# PIC32MM0064GPM064 device description
Architecture: MIPS; Family: PIC32MM1387; Series: PIC32MM
Registers are 32-bit, read-write, no defined reset value unless marked. A register's access mark holds for its fields unless they carry their own. Offsets are from the block's base; [hi:lo] are bit positions; {n}, {i} and the like mark numbered series; 'fields as' and 'values as' point back to an identical list.

## CLC
Instances: CLC 0x1f802480 in periph0
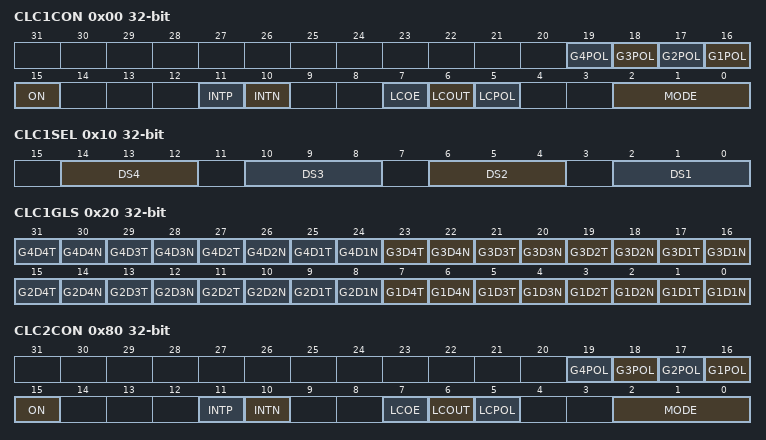
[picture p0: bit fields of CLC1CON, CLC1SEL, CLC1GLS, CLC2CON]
0x00 CLC1CON
  [n+15] G{n}POL (n=1..4) — Gate {n} Polarity Control bit
    1=The output of Channel {n} logic is inverted when applied to the logic cell; 0=The output of Channel {n} logic is not inverted
  [15] ON — CLCx Enable bit
    1=CLCx is enabled and mixing input signals; 0=CLCx is disabled and has logic zero outputs
  [11] INTP — CLCx Positive Edge Interrupt Enable bit
    1=Interrupt will be generated when a rising edge occurs on LCOUT; 0=Interrupt will not be generated
  [10] INTN — CLCx Negative Edge Interrupt Enable bit
    1=Interrupt will be generated when a falling edge occurs on LCOUT; 0=Interrupt will not be generated
  [7] LCOE — CLCx Port Enable bit
    1=CLCx port pin output is enabled; 0=CLCx port pin output is disabled
  [6] LCOUT — CLCx Data Output Status bit
    1=CLCx output high; 0=CLCx output low
  [5] LCPOL — CLCx Output Polarity Control bit
    1=The output of the module is inverted; 0=The output of the module is not inverted
  [2:0] MODE — CLCx Mode bits
    7=Cell is a 1-input transparent latch with S and R; 6=Cell is a JK flip-flop with R; 5=Cell is a 2-input D flip-flop with R; 4=Cell is a 1-input D flip-flop with S and R; 3=Cell is an SR latch; 2=Cell is a 4-input AND; 1=Cell is an OR-XOR; 0=Cell is a AND-OR
0x10 CLC1SEL
  [14:12] DS4 — Data Selection MUX 4 Signal Selection bits
    7=SCCP5 OCMP compare match event; 6=MCCP1 OCMP compare match event; 5=RTCC event; 4=CMP3 out; 3=SPI1 SDI1 in; 2=SCCP5 OCM5 output; 1=CLC2 out; 0=CLCINB I/O pin
  [10:8] DS3 — Data Selection MUX 3 Signal Selection bits
    7=SCCP5 OCMP compare match event; 6=SCCP4 OCMP compare match event; 5=SCCP4 OCM4 output; 4=UART1 RX In; 3=SPI1 SDO1 Out; 2=CMP2 out; 1=CLC1 Out; 0=CLCINA I/O pin
  [6:4] DS2 — Data Selection MUX 2 Signal Selection bits
    6=MCCP1 OCMP compare match event; 5=DMA Channel 0 interrupt; 4=ADC End of Conversion; 3=UART1 TX Out; 2=CMP1 out; 1=CLC2 out; 0=CLCINB I/O pin
  [2:0] DS1 — Data Selection MUX 1 Signal Selection bits
    7=MCCP1 OCM1C Output; 6=MCCP1 OCM1B Output; 5=MCCP1 OCM1A Output; 4=REFO1 Clock Output; 3=LPRC Clock; 2=SOSC Clock; 1=System Clock; 0=CLCINA I/O pin
0x20 CLC1GLS
  [8n-1] G{n}D4T (n=1..4), [8n-2] G{n}D4N (n=1..4), [8n-3] G{n}D3T (n=1..4), [8n-4] G{n}D3N (n=1..4), [8n-5] G{n}D2T (n=1..4), [8n-6] G{n}D2N (n=1..4), [8n-7] G{n}D1T (n=1..4), [8n-8] G{n}D1N (n=1..4)
0x80 CLC2CON
  fields as CLC1CON
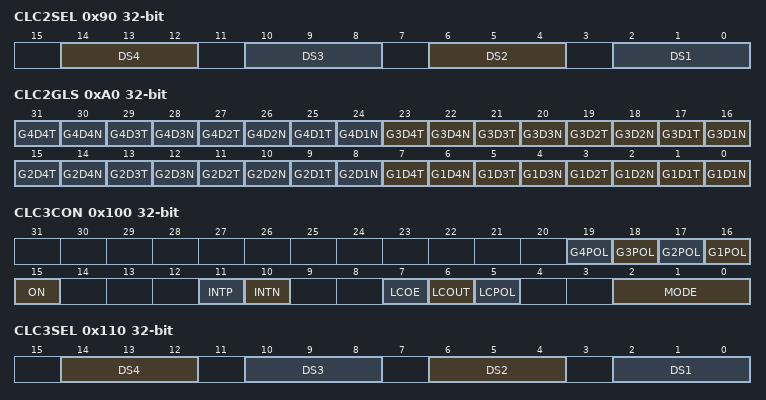
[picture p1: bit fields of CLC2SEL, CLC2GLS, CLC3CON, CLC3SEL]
0x90 CLC2SEL
  [14:12] DS4 — Data Selection MUX 4 Signal Selection bits
    7=SCCP5 OCMP compare match event; 6=MCCP1 OCMP compare match event; 5=RTCC event; 4=CMP3 out; 3=SPI2 SDI2 in; 2=SCCP5 OCM5 Output; 1=CLC1 out; 0=CLCINB I/O pin
  [10:8] DS3 — Data Selection MUX 3 Signal Selection bits
    7=SCCP5 OCMP compare match event; 6=SCCP4 OCMP compare match event; 5=SCCP4 OCM4 output; 4=UART2 RX In; 3=SPI2 SDO2 Out; 2=CMP2 out; 1=CLC2 Out; 0=CLCINA I/O pin
  [6:4] DS2 — Data Selection MUX 2 Signal Selection bits
    6=MCCP1 OCMP compare match event; 5=DMA Channel 1 interrupt; 4=ADC End of Conversion; 3=UART2 TX Out; 2=CMP1 out; 1=CLC1 out; 0=CLCINB I/O pin
  [2:0] DS1 — Data Selection MUX 1 Signal Selection bits
    7=MCCP1 OCM1F Output; 6=MCCP1 OCM1E Output; 5=MCCP1 OCM1D Output; 4=REFO1 Clock Output; 3=LPRC Clock; 2=SOSC Clock; 1=System Clock; 0=CLCINA I/O pin
0xA0 CLC2GLS
  fields as CLC1GLS
0x100 CLC3CON
  fields as CLC1CON
0x110 CLC3SEL
  [14:12] DS4 — Data Selection MUX 4 Signal Selection bits
    7=SCCP7 OCMP compare match event; 6=MCCP2 OCMP compare match event; 5=RTCC event; 4=CMP3 out; 3=SPI3 SDI3 in; 2=SCCP7 OCM7A Output; 1=CLC4 out; 0=CLCINB I/O pin
  [10:8] DS3 — Data Selection MUX 3 Signal Selection bits
    7=SCCP7 OCMP compare match event; 6=SCCP6 OCMP compare match event; 5=SCCP6 OCM6 output; 4=UART3 RX In; 3=SPI3 SDO3 Out; 2=CMP2 out; 1=CLC3 Out; 0=CLCINA I/O pin
  [6:4] DS2 — Data Selection MUX 2 Signal Selection bits
    6=MCCP2 OCMP compare match event; 5=DMA channel 0 interrupt; 4=ADC End of Conversion; 3=UART3 TX Out; 2=CMP1 out; 1=CLC4 out; 0=CLCINB I/O pin
  [2:0] DS1 — Data Selection MUX 1 Signal Selection bits
    7=MCCP2 OCM1C Output; 6=MCCP2 OCM1B Output; 5=MCCP2 OCM1A Output; 4=REFO1 Clock Output; 3=LPRC Clock; 2=SOSC Clock; 1=System Clock; 0=CLCINA I/O pin
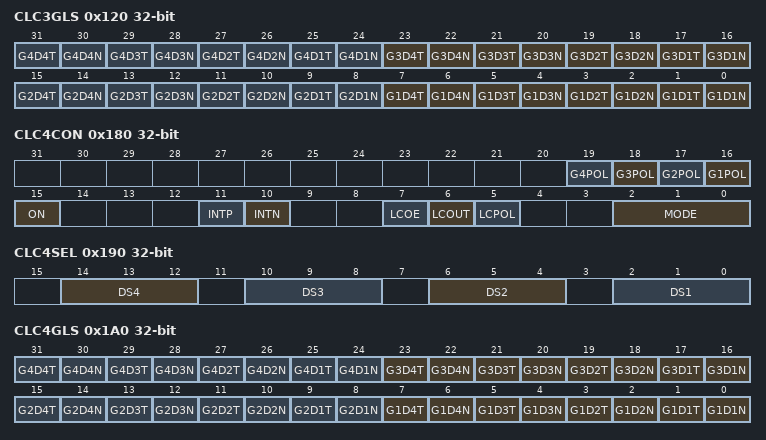
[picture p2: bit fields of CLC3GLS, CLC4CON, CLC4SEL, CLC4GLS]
0x120 CLC3GLS
  fields as CLC1GLS
0x180 CLC4CON
  fields as CLC1CON
0x190 CLC4SEL
  [14:12] DS4 — Data Selection MUX 4 Signal Selection bits
    7=SCCP7 OCMP compare match event; 6=MCCP3 OCMP compare match event; 5=RTCC event; 4=CMP3 out; 2=SCCP7 OCM3 Output; 1=CLC3 out; 0=CLCINB I/O pin
  [10:8] DS3 — Data Selection MUX 3 Signal Selection bits
    7=SCCP7 OCMP compare match event; 6=SCCP6 OCMP compare match event; 5=SCCP6 OCM2 output; 2=CMP2 out; 1=CLC4 Out; 0=CLCINA I/O pin
  [6:4] DS2 — Data Selection MUX 2 Signal Selection bits
    6=MCCP3 OCMP compare match event; 5=DMA channel 1 interrupt; 4=ADC End of Conversion; 2=CMP1 out; 1=CLC3 out; 0=CLCINB I/O pin
  [2:0] DS1 — Data Selection MUX 1 Signal Selection bits
    7=MCCP3 OCM1F Output; 6=MCCP3 OCM1E Output; 5=MCCP3 OCM1D Output; 4=REFO1 Clock Output; 3=LPRC Clock; 2=SOSC Clock; 1=System Clock; 0=CLCINA I/O pin
0x1A0 CLC4GLS
  fields as CLC1GLS

## Notices in the file
Copyright (c) 2019 Microchip Technology Inc.
SPDX-License-Identifier: Apache-2.0
Licensed under the Apache License, Version 2.0 (the "License");
you may not use this file except in compliance with the License.
You may obtain a copy of the License at
http://www.apache.org/licenses/LICENSE-2.0
Unless required by applicable law or agreed to in writing, software
distributed under the License is distributed on an "AS IS" BASIS,
WITHOUT WARRANTIES OR CONDITIONS OF ANY KIND, either express or implied.
See the License for the specific language governing permissions and
limitations under the License.
